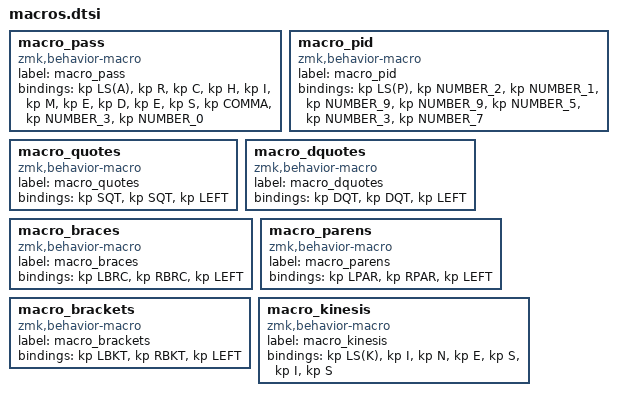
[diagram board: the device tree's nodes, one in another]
macro_pass: macro_pass{
compatible = "zmk,behavior-macro";
label = "macro_pass";
#binding-cells = <0>;
bindings = <&kp LS(A)>, <&kp R>, <&kp C>, <&kp H>, <&kp I>, <&kp M>, <&kp E>, <&kp D>, <&kp E>, <&kp S>, <&kp COMMA>, <&kp NUMBER_3>, <&kp NUMBER_0>;
};
macro_pid: macro_pid{
compatible = "zmk,behavior-macro";
label = "macro_pid";
#binding-cells = <0>;
bindings = <&kp LS(P)>, <&kp NUMBER_2>, <&kp NUMBER_1>, <&kp NUMBER_9>, <&kp NUMBER_9>, <&kp NUMBER_5>, <&kp NUMBER_3>, <&kp NUMBER_7>;
};
macro_quotes: macro_quotes{
compatible = "zmk,behavior-macro";
label = "macro_quotes";
#binding-cells = <0>;
bindings = <&kp SQT>, <&kp SQT>, <&kp LEFT>;
};
macro_dquotes: macro_dquotes{
compatible = "zmk,behavior-macro";
label = "macro_dquotes";
#binding-cells = <0>;
bindings = <&kp DQT>, <&kp DQT>, <&kp LEFT>;
};
macro_braces: macro_braces{
compatible = "zmk,behavior-macro";
label = "macro_braces";
#binding-cells = <0>;
bindings = <&kp LBRC>, <&kp RBRC>, <&kp LEFT>;
};
macro_parens: macro_parens{
compatible = "zmk,behavior-macro";
label = "macro_parens";
#binding-cells = <0>;
bindings = <&kp LPAR>, <&kp RPAR>, <&kp LEFT>;
};
macro_brackets: macro_brackets{
compatible = "zmk,behavior-macro";
label = "macro_brackets";
#binding-cells = <0>;
bindings = <&kp LBKT>, <&kp RBKT>, <&kp LEFT>;
};
macro_kinesis: macro_kinesis{
compatible = "zmk,behavior-macro";
label = "macro_kinesis";
#binding-cells = <0>;
bindings = <&kp LS(K)>, <&kp I>, <&kp N>, <&kp E>, <&kp S>, <&kp I>, <&kp S>;
};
